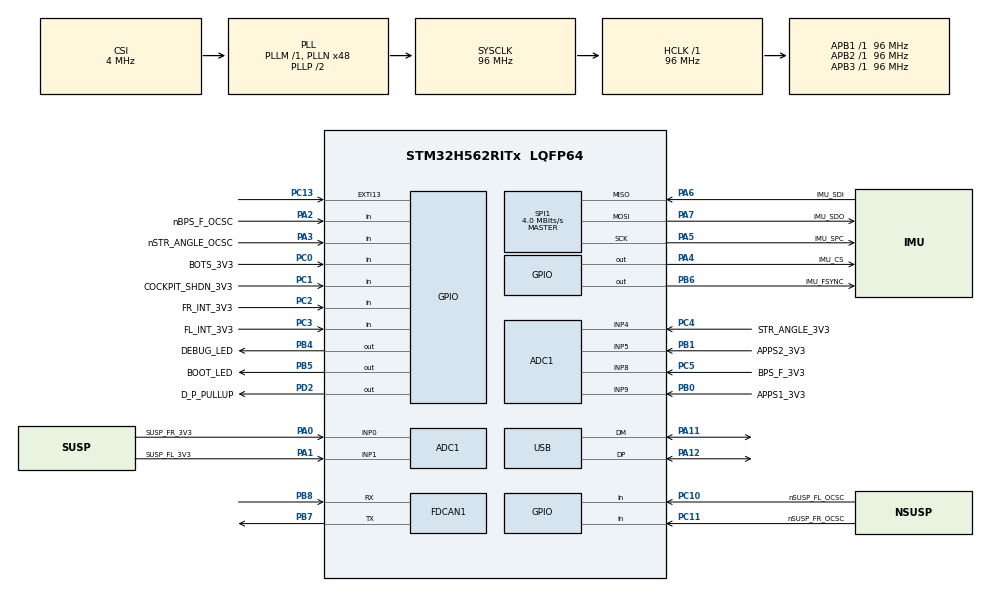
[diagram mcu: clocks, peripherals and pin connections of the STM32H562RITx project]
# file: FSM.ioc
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ADC1.Channel-3\#ChannelRegularConversion=ADC_CHANNEL_1
ADC1.Channel-4\#ChannelRegularConversion=ADC_CHANNEL_0
ADC1.Channel-5\#ChannelRegularConversion=ADC_CHANNEL_5
ADC1.Channel-6\#ChannelRegularConversion=ADC_CHANNEL_8
ADC1.Channel-7\#ChannelRegularConversion=ADC_CHANNEL_4
ADC1.Channel-8\#ChannelRegularConversion=ADC_CHANNEL_9
ADC1.ContinuousConvMode=DISABLE
ADC1.ConversionDataManagement=ADC_CONVERSIONDATA_DMA_CIRCULAR
ADC1.DMAContinuousRequests=ENABLE
ADC1.EOCSelection=ADC_EOC_SEQ_CONV
ADC1.ExternalTrigConv=ADC_EXTERNALTRIG_T2_TRGO
ADC1.MonitoredBy-3\#ChannelRegularConversion=__NULL
ADC1.MonitoredBy-4\#ChannelRegularConversion=__NULL
ADC1.MonitoredBy-5\#ChannelRegularConversion=__NULL
ADC1.MonitoredBy-6\#ChannelRegularConversion=__NULL
ADC1.MonitoredBy-7\#ChannelRegularConversion=__NULL
ADC1.MonitoredBy-8\#ChannelRegularConversion=__NULL
ADC1.NbrOfConversion=6
ADC1.NbrOfConversionFlag=1
ADC1.OffsetNumber-3\#ChannelRegularConversion=ADC_OFFSET_NONE
ADC1.OffsetNumber-4\#ChannelRegularConversion=ADC_OFFSET_NONE
ADC1.OffsetNumber-5\#ChannelRegularConversion=ADC_OFFSET_NONE
ADC1.OffsetNumber-6\#ChannelRegularConversion=ADC_OFFSET_NONE
ADC1.OffsetNumber-7\#ChannelRegularConversion=ADC_OFFSET_NONE
ADC1.OffsetNumber-8\#ChannelRegularConversion=ADC_OFFSET_NONE
ADC1.Rank-3\#ChannelRegularConversion=1
ADC1.Rank-4\#ChannelRegularConversion=2
ADC1.Rank-5\#ChannelRegularConversion=3
ADC1.Rank-6\#ChannelRegularConversion=4
ADC1.Rank-7\#ChannelRegularConversion=5
ADC1.Rank-8\#ChannelRegularConversion=6
ADC1.SamplingTime-3\#ChannelRegularConversion=ADC_SAMPLETIME_47CYCLES_5
ADC1.SamplingTime-4\#ChannelRegularConversion=ADC_SAMPLETIME_47CYCLES_5
ADC1.SamplingTime-5\#ChannelRegularConversion=ADC_SAMPLETIME_47CYCLES_5
ADC1.SamplingTime-6\#ChannelRegularConversion=ADC_SAMPLETIME_47CYCLES_5
ADC1.SamplingTime-7\#ChannelRegularConversion=ADC_SAMPLETIME_47CYCLES_5
ADC1.SamplingTime-8\#ChannelRegularConversion=ADC_SAMPLETIME_47CYCLES_5
ADC1.master=1
BOOTPATH.BootPathName=LEGACY
BOOTPATH.UserSelectedBootPath=LEGACY
CORTEX_M33_NS.userName=CORTEX_M33
FDCAN1.AutoRetransmission=ENABLE
FDCAN1.CalculateBaudRateNominal=1000000
FDCAN1.CalculateTimeBitNominal=1000
FDCAN1.CalculateTimeQuantumNominal=62.5
FDCAN1.DataPrescaler=3
FDCAN1.DataSyncJumpWidth=2
FDCAN1.DataTimeSeg1=5
FDCAN1.DataTimeSeg2=2
FDCAN1.ExtFiltersNbr=1
FDCAN1.FrameFormat=FDCAN_FRAME_FD_NO_BRS
FDCAN1.NominalPrescaler=6
FDCAN1.NominalSyncJumpWidth=2
FDCAN1.NominalTimeSeg1=13
FDCAN1.NominalTimeSeg2=2
FDCAN1.StdFiltersNbr=1
GPDMA1.CIRCULARMODE_GPDMACH0=ENABLE
GPDMA1.DESTDATAWIDTH_GPDMACH0=DMA_DEST_DATAWIDTH_HALFWORD
GPDMA1.DESTINC_GPDMACH0=DMA_DINC_INCREMENTED
GPDMA1.IPHANDLE_GPDMACH0-SIMPLEREQUEST_GPDMACH0=__NULL
GPDMA1.REQUEST_GPDMACH0=GPDMA1_REQUEST_ADC1
GPDMA1.SRCDATAWIDTH_GPDMACH0=DMA_SRC_DATAWIDTH_HALFWORD
GPDMA1.TRANSFERALLOCATEDPORTDEST_GPDMACH0=DMA_DEST_ALLOCATED_PORT0
IWDG.Reload=LSI_FREQUENCY/IWDG_PRESCALER/IWDG_RESET_FREQUENCY
Mcu.Family=STM32H5
Mcu.Name=STM32H562RITx
Mcu.Package=LQFP64
Mcu.UserConstants=TIM2_ARR,(TIMx_FREQUENCY / TIM2_PRESCALER / TIM2_FREQUENCY);TIM2_PRESCALER,250;TIM2_FREQUENCY,1000;TIMx_FREQUENCY,96000000;IWDG_RESET_FREQUENCY,5;IWDG_PRESCALER,4;LSI_FREQUENCY,32000
NVIC.ADC1_IRQn=true\:5\:0\:true\:false\:true\:true\:true\:true
NVIC.EXTI13_IRQn=true\:5\:0\:true\:false\:true\:true\:true\:true
NVIC.FDCAN1_IT0_IRQn=true\:5\:0\:true\:false\:true\:true\:true\:true
NVIC.FDCAN1_IT1_IRQn=true\:5\:0\:true\:false\:true\:true\:true\:true
NVIC.GPDMA1_Channel0_IRQn=true\:5\:0\:true\:false\:true\:false\:true\:true
NVIC.PriorityGroup=NVIC_PRIORITYGROUP_4
NVIC.SPI1_IRQn=true\:5\:0\:true\:false\:true\:true\:true\:true
NVIC.TIM2_IRQn=true\:5\:0\:true\:false\:true\:true\:true\:true
NVIC.TIM6_IRQn=true\:15\:0\:false\:false\:true\:false\:true\:true
NVIC.TIM7_IRQn=true\:5\:0\:true\:false\:true\:true\:true\:true
NVIC.TimeBase=TIM6_IRQn
NVIC.TimeBaseIP=TIM6
NVIC.USB_DRD_FS_IRQn=true\:5\:0\:true\:false\:true\:true\:true\:true
PA0.GPIO_Label=SUSP_FR_3V3
PA0.Signal=ADCx_INP0
PA1.GPIO_Label=SUSP_FL_3V3
PA1.Signal=ADCx_INP1
PA11.Mode=Device
PA11.Signal=USB_DM
PA12.Mode=Device
PA12.Signal=USB_DP
PA13(JTMS/SWDIO).Mode=Trace_Asynchronous_SW
PA13(JTMS/SWDIO).Signal=DEBUG_JTMS-SWDIO
PA14(JTCK/SWCLK).Mode=Trace_Asynchronous_SW
PA14(JTCK/SWCLK).Signal=DEBUG_JTCK-SWCLK
PA2.GPIO_Label=nBPS_F_OCSC
PA2.Signal=GPIO_Input
PA3.GPIO_Label=nSTR_ANGLE_OCSC
PA3.Signal=GPIO_Input
PA4.GPIO_Label=IMU_CS
PA4.PinState=GPIO_PIN_SET
PA4.Signal=GPIO_Output
PA5.GPIO_Label=IMU_SPC
PA5.Mode=Full_Duplex_Master
PA5.Signal=SPI1_SCK
PA6.GPIO_Label=IMU_SDI
PA6.Mode=Full_Duplex_Master
PA6.Signal=SPI1_MISO
PA7.GPIO_Label=IMU_SDO
PA7.Mode=Full_Duplex_Master
PA7.Signal=SPI1_MOSI
PB0.GPIO_Label=APPS1_3V3
PB0.Signal=ADCx_INP9
PB1.GPIO_Label=APPS2_3V3
PB1.Signal=ADCx_INP5
PB3(JTDO/TRACESWO).Mode=Trace_Asynchronous_SW
PB3(JTDO/TRACESWO).Signal=DEBUG_JTDO-SWO
PB4(NJTRST).GPIO_Label=DEBUG_LED
PB4(NJTRST).Signal=GPIO_Output
PB5.GPIO_Label=BOOT_LED
PB5.Signal=GPIO_Output
PB6.GPIO_Label=IMU_FSYNC
PB6.Signal=GPIO_Output
PB7.Mode=FDCAN_Activate
PB7.Signal=FDCAN1_TX
PB8.Mode=FDCAN_Activate
PB8.Signal=FDCAN1_RX
PC0.GPIO_Label=BOTS_3V3
PC0.Signal=GPIO_Input
PC1.GPIO_Label=COCKPIT_SHDN_3V3
PC1.Signal=GPIO_Input
PC10.GPIO_Label=nSUSP_FL_OCSC
PC10.Signal=GPIO_Input
PC11.GPIO_Label=nSUSP_FR_OCSC
PC11.Signal=GPIO_Input
PC13.Signal=GPXTI13
PC2.GPIO_Label=FR_INT_3V3
PC2.Signal=GPIO_Input
PC3.GPIO_Label=FL_INT_3V3
PC3.Signal=GPIO_Input
PC4.GPIO_Label=STR_ANGLE_3V3
PC4.Signal=ADCx_INP4
PC5.GPIO_Label=BPS_F_3V3
PC5.Signal=ADCx_INP8
PD2.GPIO_Label=D_P_PULLUP
PD2.GPIO_ModeDefaultOutputPP=GPIO_MODE_OUTPUT_PP
PD2.GPIO_PuPd=GPIO_NOPULL
PD2.Signal=GPIO_Output
PH0-OSC_IN(PH0).Mode=HSE-External-Oscillator
PH0-OSC_IN(PH0).Signal=RCC_OSC_IN
PH1-OSC_OUT(PH1).Mode=HSE-External-Oscillator
PH1-OSC_OUT(PH1).Signal=RCC_OSC_OUT
ProjectManager.HeapSize=0x200
ProjectManager.StackSize=0x400
ProjectManager.TargetToolchain=STM32CubeIDE
RCC.ADCFreq_Value=96000000
RCC.AHBFreq_Value=96000000
RCC.APB1Freq_Value=96000000
RCC.APB1TimFreq_Value=96000000
RCC.APB2Freq_Value=96000000
RCC.APB2TimFreq_Value=96000000
RCC.APB3Freq_Value=96000000
RCC.CKPERSourceSelection=RCC_CLKPSOURCE_HSE
RCC.CSI_VALUE=4000000
RCC.CortexFreq_Value=96000000
RCC.EPOD_VALUE=4000000
RCC.FDCANClockSelection=RCC_FDCANCLKSOURCE_PLL1Q
RCC.HCLKFreq_Value=96000000
RCC.HSE_VALUE=8000000
RCC.HSI48_VALUE=48000000
RCC.HSI_VALUE=64000000
RCC.LSE_VALUE=32768
RCC.LSIRC_VALUE=32000
RCC.PLL2FRACN=0
RCC.PLL2Source=RCC_PLL2_SOURCE_HSE
RCC.PLL3FRACN=0
RCC.PLL3Source=RCC_PLL3_SOURCE_HSE
RCC.PLLFRACN=0
RCC.PLLN=48
RCC.SPI1CLockSelection=RCC_SPI1CLKSOURCE_CLKP
RCC.SYSCLKFreq_VALUE=96000000
RCC.SYSCLKSource=RCC_SYSCLKSOURCE_PLLCLK
RCC.USBFreq_Value=48000000
RCC.VCOOutputFreq_Value=192000000
SH.ADCx_INP0.0=ADC1_INP0,IN0-Single-Ended
SH.ADCx_INP1.0=ADC1_INP1,IN1-Single-Ended
SH.ADCx_INP4.0=ADC1_INP4,IN4-Single-Ended
SH.ADCx_INP5.0=ADC1_INP5,IN5-Single-Ended
SH.ADCx_INP8.0=ADC1_INP8,IN8-Single-Ended
SH.ADCx_INP9.0=ADC1_INP9,IN9-Single-Ended
SPI1.BaudRatePrescaler=SPI_BAUDRATEPRESCALER_2
SPI1.CalculateBaudRate=4.0 MBits/s
SPI1.DataSize=SPI_DATASIZE_8BIT
SPI1.Direction=SPI_DIRECTION_2LINES
SPI1.Mode=SPI_MODE_MASTER
SPI1.VirtualType=VM_MASTER
TIM2.AutoReloadPreload=TIM_AUTORELOAD_PRELOAD_ENABLE
TIM2.PeriodNoDither=TIM2_ARR -1
TIM2.Prescaler=TIM2_PRESCALER - 1
TIM2.TIM_MasterOutputTrigger=TIM_TRGO_UPDATE
TIM7.PeriodNoDither=960-1
TIM7.Prescaler=10-1
USB.VirtualMode=Device_Only
VP_BOOTPATH_VS_BOOTPATH.Mode=BP_Activate
VP_CORTEX_M33_NS_VS_Hclk.Mode=Hclk_Mode
VP_GPDMA1_VS_GPDMACH0.Mode=SIMPLEREQUEST_GPDMACH0
VP_IWDG_VS_IWDG.Mode=IWDG_Activate
VP_MEMORYMAP_VS_MEMORYMAP.Mode=CurAppReg
VP_PWR_VS_LPOM.Mode=PowerOptimisation
VP_PWR_VS_SECSignals.Mode=Security/Privilege
VP_SYS_VS_tim6.Mode=TIM6
VP_TIM2_VS_ClockSourceINT.Mode=Internal
VP_TIM7_VS_ClockSourceINT.Mode=Enable_Timer
board=custom

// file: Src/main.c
/* USER CODE BEGIN Header */
/**
 ******************************************************************************
 * @file           : main.c
 * @brief          : Main program body
 ******************************************************************************
 * @attention
 *
 * Copyright (c) 2025 STMicroelectronics.
 * All rights reserved.
 *
 * This software is licensed under terms that can be found in the LICENSE file
 * in the root directory of this software component.
 * If no LICENSE file comes with this software, it is provided AS-IS.
 *
 ******************************************************************************
 */
/* USER CODE END Header */
#include "main.h"

/* USER CODE BEGIN Includes */
#include "tasks.h"
#include "hw_error.hpp"
/* USER CODE END Includes */

ADC_HandleTypeDef hadc1;
DMA_NodeTypeDef   Node_GPDMA1_Channel0;
DMA_QListTypeDef  List_GPDMA1_Channel0;
DMA_HandleTypeDef handle_GPDMA1_Channel0;

FDCAN_HandleTypeDef hfdcan1;

IWDG_HandleTypeDef hiwdg;

SPI_HandleTypeDef hspi1;

TIM_HandleTypeDef htim2;
TIM_HandleTypeDef htim7;

PCD_HandleTypeDef hpcd_USB_DRD_FS;

void        SystemClock_Config(void);
void        PeriphCommonClock_Config(void);
static void MX_GPIO_Init(void);
static void MX_GPDMA1_Init(void);
static void MX_ADC1_Init(void);
static void MX_FDCAN1_Init(void);
static void MX_USB_PCD_Init(void);
static void MX_SPI1_Init(void);
static void MX_TIM2_Init(void);
static void MX_IWDG_Init(void);
static void MX_TIM7_Init(void);

int main(void)
{
    /* USER CODE BEGIN 1 */
    tasks_preInit();
    /* USER CODE END 1 */

    /* MCU Configuration--------------------------------------------------------*/

    /* Reset of all peripherals, Initializes the Flash interface and the Systick. */
    HAL_Init();

    /* Configure the system clock */
    SystemClock_Config();

    /* Configure the peripherals common clocks */
    PeriphCommonClock_Config();

    /* Initialize all configured peripherals */
    MX_GPIO_Init();
    MX_GPDMA1_Init();
    MX_ADC1_Init();
    MX_FDCAN1_Init();
    MX_USB_PCD_Init();
    MX_SPI1_Init();
    MX_TIM2_Init();
    MX_IWDG_Init();
    MX_TIM7_Init();
    /* USER CODE BEGIN 2 */
    tasks_init();
    /* USER CODE END 2 */

    /* Infinite loop */
    while (1)
    {

    }
}

void SystemClock_Config(void)
{
    RCC_OscInitTypeDef RCC_OscInitStruct = { 0 };
    RCC_ClkInitTypeDef RCC_ClkInitStruct = { 0 };

    /** Configure the main internal regulator output voltage
     */
    __HAL_PWR_VOLTAGESCALING_CONFIG(PWR_REGULATOR_VOLTAGE_SCALE3);

    while (!__HAL_PWR_GET_FLAG(PWR_FLAG_VOSRDY))
    {
    }

    /** Initializes the RCC Oscillators according to the specified parameters
     * in the RCC_OscInitTypeDef structure.
     */
    RCC_OscInitStruct.OscillatorType =
        RCC_OSCILLATORTYPE_HSI48 | RCC_OSCILLATORTYPE_LSI | RCC_OSCILLATORTYPE_HSE | RCC_OSCILLATORTYPE_CSI;
    RCC_OscInitStruct.HSEState            = RCC_HSE_ON;
    RCC_OscInitStruct.LSIState            = RCC_LSI_ON;
    RCC_OscInitStruct.HSI48State          = RCC_HSI48_ON;
    RCC_OscInitStruct.CSIState            = RCC_CSI_ON;
    RCC_OscInitStruct.CSICalibrationValue = RCC_CSICALIBRATION_DEFAULT;
    RCC_OscInitStruct.PLL.PLLState        = RCC_PLL_ON;
    RCC_OscInitStruct.PLL.PLLSource       = RCC_PLL1_SOURCE_CSI;
    RCC_OscInitStruct.PLL.PLLM            = 1;
    RCC_OscInitStruct.PLL.PLLN            = 48;
    RCC_OscInitStruct.PLL.PLLP            = 2;
    RCC_OscInitStruct.PLL.PLLQ            = 2;
    RCC_OscInitStruct.PLL.PLLR            = 2;
    RCC_OscInitStruct.PLL.PLLRGE          = RCC_PLL1_VCIRANGE_2;
    RCC_OscInitStruct.PLL.PLLVCOSEL       = RCC_PLL1_VCORANGE_WIDE;
    RCC_OscInitStruct.PLL.PLLFRACN        = 0;
    if (HAL_RCC_OscConfig(&RCC_OscInitStruct) != HAL_OK)
    {
        Error_Handler();
    }

    /** Initializes the CPU, AHB and APB buses clocks
     */
    RCC_ClkInitStruct.ClockType =
        RCC_CLOCKTYPE_HCLK | RCC_CLOCKTYPE_SYSCLK | RCC_CLOCKTYPE_PCLK1 | RCC_CLOCKTYPE_PCLK2 | RCC_CLOCKTYPE_PCLK3;
    RCC_ClkInitStruct.SYSCLKSource   = RCC_SYSCLKSOURCE_PLLCLK;
    RCC_ClkInitStruct.AHBCLKDivider  = RCC_SYSCLK_DIV1;
    RCC_ClkInitStruct.APB1CLKDivider = RCC_HCLK_DIV1;
    RCC_ClkInitStruct.APB2CLKDivider = RCC_HCLK_DIV1;
    RCC_ClkInitStruct.APB3CLKDivider = RCC_HCLK_DIV1;

    if (HAL_RCC_ClockConfig(&RCC_ClkInitStruct, FLASH_LATENCY_4) != HAL_OK)
    {
        Error_Handler();
    }

    /** Configure the programming delay
     */
    __HAL_FLASH_SET_PROGRAM_DELAY(FLASH_PROGRAMMING_DELAY_2);
}

void PeriphCommonClock_Config(void)
{
    RCC_PeriphCLKInitTypeDef PeriphClkInitStruct = { 0 };

    /** Initializes the peripherals clock
     */
    PeriphClkInitStruct.PeriphClockSelection = RCC_PERIPHCLK_CKPER;
    PeriphClkInitStruct.CkperClockSelection  = RCC_CLKPSOURCE_HSE;
    if (HAL_RCCEx_PeriphCLKConfig(&PeriphClkInitStruct) != HAL_OK)
    {
        Error_Handler();
    }
}

static void MX_ADC1_Init(void)
{

    ADC_ChannelConfTypeDef sConfig = { 0 };

    /** Common config
     */
    hadc1.Instance                   = ADC1;
    hadc1.Init.ClockPrescaler        = ADC_CLOCK_ASYNC_DIV2;
    hadc1.Init.Resolution            = ADC_RESOLUTION_12B;
    hadc1.Init.DataAlign             = ADC_DATAALIGN_RIGHT;
    hadc1.Init.ScanConvMode          = ADC_SCAN_ENABLE;
    hadc1.Init.EOCSelection          = ADC_EOC_SEQ_CONV;
    hadc1.Init.LowPowerAutoWait      = DISABLE;
    hadc1.Init.ContinuousConvMode    = DISABLE;
    hadc1.Init.NbrOfConversion       = 6;
    hadc1.Init.DiscontinuousConvMode = DISABLE;
    hadc1.Init.ExternalTrigConv      = ADC_EXTERNALTRIG_T2_TRGO;
    hadc1.Init.ExternalTrigConvEdge  = ADC_EXTERNALTRIGCONVEDGE_RISING;
    hadc1.Init.DMAContinuousRequests = ENABLE;
    hadc1.Init.SamplingMode          = ADC_SAMPLING_MODE_NORMAL;
    hadc1.Init.Overrun               = ADC_OVR_DATA_PRESERVED;
    hadc1.Init.OversamplingMode      = DISABLE;
    if (HAL_ADC_Init(&hadc1) != HAL_OK)
    {
        Error_Handler();
    }

    /** Configure Regular Channel
     */
    sConfig.Channel      = ADC_CHANNEL_1;
    sConfig.Rank         = ADC_REGULAR_RANK_1;
    sConfig.SamplingTime = ADC_SAMPLETIME_47CYCLES_5;
    sConfig.SingleDiff   = ADC_SINGLE_ENDED;
    sConfig.OffsetNumber = ADC_OFFSET_NONE;
    sConfig.Offset       = 0;
    if (HAL_ADC_ConfigChannel(&hadc1, &sConfig) != HAL_OK)
    {
        Error_Handler();
    }

    /** Configure Regular Channel
     */
    sConfig.Channel = ADC_CHANNEL_0;
    sConfig.Rank    = ADC_REGULAR_RANK_2;
    if (HAL_ADC_ConfigChannel(&hadc1, &sConfig) != HAL_OK)
    {
        Error_Handler();
    }

    /** Configure Regular Channel
     */
    sConfig.Channel = ADC_CHANNEL_5;
    sConfig.Rank    = ADC_REGULAR_RANK_3;
    if (HAL_ADC_ConfigChannel(&hadc1, &sConfig) != HAL_OK)
    {
        Error_Handler();
    }

    /** Configure Regular Channel
     */
    sConfig.Channel = ADC_CHANNEL_8;
    sConfig.Rank    = ADC_REGULAR_RANK_4;
    if (HAL_ADC_ConfigChannel(&hadc1, &sConfig) != HAL_OK)
    {
        Error_Handler();
    }

    /** Configure Regular Channel
     */
    sConfig.Channel = ADC_CHANNEL_4;
    sConfig.Rank    = ADC_REGULAR_RANK_5;
    if (HAL_ADC_ConfigChannel(&hadc1, &sConfig) != HAL_OK)
    {
        Error_Handler();
    }

    /** Configure Regular Channel
     */
    sConfig.Channel = ADC_CHANNEL_9;
    sConfig.Rank    = ADC_REGULAR_RANK_6;
    if (HAL_ADC_ConfigChannel(&hadc1, &sConfig) != HAL_OK)
    {
        Error_Handler();
    }
}

static void MX_FDCAN1_Init(void)
{

    hfdcan1.Instance                  = FDCAN1;
    hfdcan1.Init.ClockDivider         = FDCAN_CLOCK_DIV1;
    hfdcan1.Init.FrameFormat          = FDCAN_FRAME_FD_NO_BRS;
    hfdcan1.Init.Mode                 = FDCAN_MODE_NORMAL;
    hfdcan1.Init.AutoRetransmission   = ENABLE;
    hfdcan1.Init.TransmitPause        = DISABLE;
    hfdcan1.Init.ProtocolException    = DISABLE;
    hfdcan1.Init.NominalPrescaler     = 6;
    hfdcan1.Init.NominalSyncJumpWidth = 2;
    hfdcan1.Init.NominalTimeSeg1      = 13;
    hfdcan1.Init.NominalTimeSeg2      = 2;
    hfdcan1.Init.DataPrescaler        = 3;
    hfdcan1.Init.DataSyncJumpWidth    = 2;
    hfdcan1.Init.DataTimeSeg1         = 5;
    hfdcan1.Init.DataTimeSeg2         = 2;
    hfdcan1.Init.StdFiltersNbr        = 1;
    hfdcan1.Init.ExtFiltersNbr        = 1;
    hfdcan1.Init.TxFifoQueueMode      = FDCAN_TX_FIFO_OPERATION;
    if (HAL_FDCAN_Init(&hfdcan1) != HAL_OK)
    {
        Error_Handler();
    }
}

static void MX_GPDMA1_Init(void)
{

    /* Peripheral clock enable */
    __HAL_RCC_GPDMA1_CLK_ENABLE();

    /* GPDMA1 interrupt Init */
    HAL_NVIC_SetPriority(GPDMA1_Channel0_IRQn, 5, 0);
    HAL_NVIC_EnableIRQ(GPDMA1_Channel0_IRQn);

}

static void MX_IWDG_Init(void)
{

    /* USER CODE BEGIN IWDG_Init 1 */
#ifndef WATCHDOG_DISABLED
    /* USER CODE END IWDG_Init 1 */
    hiwdg.Instance       = IWDG;
    hiwdg.Init.Prescaler = IWDG_PRESCALER_4;
    hiwdg.Init.Window    = 4095;
    hiwdg.Init.Reload    = LSI_FREQUENCY / IWDG_PRESCALER / IWDG_RESET_FREQUENCY;
    hiwdg.Init.EWI       = 0;
    if (HAL_IWDG_Init(&hiwdg) != HAL_OK)
    {
        Error_Handler();
    }
    /* USER CODE BEGIN IWDG_Init 2 */
#endif
    /* USER CODE END IWDG_Init 2 */
}

static void MX_SPI1_Init(void)
{

    /* SPI1 parameter configuration*/
    hspi1.Instance                     = SPI1;
    hspi1.Init.Mode                    = SPI_MODE_MASTER;
    hspi1.Init.Direction               = SPI_DIRECTION_2LINES;
    hspi1.Init.DataSize                = SPI_DATASIZE_8BIT;
    hspi1.Init.CLKPolarity             = SPI_POLARITY_LOW;
    hspi1.Init.CLKPhase                = SPI_PHASE_1EDGE;
    hspi1.Init.NSS                     = SPI_NSS_SOFT;
    hspi1.Init.BaudRatePrescaler       = SPI_BAUDRATEPRESCALER_2;
    hspi1.Init.FirstBit                = SPI_FIRSTBIT_MSB;
    hspi1.Init.TIMode                  = SPI_TIMODE_DISABLE;
    hspi1.Init.CRCCalculation          = SPI_CRCCALCULATION_DISABLE;
    hspi1.Init.CRCPolynomial           = 0x7;
    hspi1.Init.NSSPMode                = SPI_NSS_PULSE_ENABLE;
    hspi1.Init.NSSPolarity             = SPI_NSS_POLARITY_LOW;
    hspi1.Init.FifoThreshold           = SPI_FIFO_THRESHOLD_01DATA;
    hspi1.Init.MasterSSIdleness        = SPI_MASTER_SS_IDLENESS_00CYCLE;
    hspi1.Init.MasterInterDataIdleness = SPI_MASTER_INTERDATA_IDLENESS_00CYCLE;
    hspi1.Init.MasterReceiverAutoSusp  = SPI_MASTER_RX_AUTOSUSP_DISABLE;
    hspi1.Init.MasterKeepIOState       = SPI_MASTER_KEEP_IO_STATE_DISABLE;
    hspi1.Init.IOSwap                  = SPI_IO_SWAP_DISABLE;
    hspi1.Init.ReadyMasterManagement   = SPI_RDY_MASTER_MANAGEMENT_INTERNALLY;
    hspi1.Init.ReadyPolarity           = SPI_RDY_POLARITY_HIGH;
    if (HAL_SPI_Init(&hspi1) != HAL_OK)
    {
        Error_Handler();
    }
}

static void MX_TIM2_Init(void)
{

    TIM_ClockConfigTypeDef  sClockSourceConfig = { 0 };
    TIM_MasterConfigTypeDef sMasterConfig      = { 0 };

    htim2.Instance               = TIM2;
    htim2.Init.Prescaler         = TIM2_PRESCALER - 1;
    htim2.Init.CounterMode       = TIM_COUNTERMODE_UP;
    htim2.Init.Period            = 383;
    htim2.Init.ClockDivision     = TIM_CLOCKDIVISION_DIV1;
    htim2.Init.AutoReloadPreload = TIM_AUTORELOAD_PRELOAD_ENABLE;
    if (HAL_TIM_Base_Init(&htim2) != HAL_OK)
    {
        Error_Handler();
    }
    sClockSourceConfig.ClockSource = TIM_CLOCKSOURCE_INTERNAL;
    if (HAL_TIM_ConfigClockSource(&htim2, &sClockSourceConfig) != HAL_OK)
    {
        Error_Handler();
    }
    sMasterConfig.MasterOutputTrigger = TIM_TRGO_UPDATE;
    sMasterConfig.MasterSlaveMode     = TIM_MASTERSLAVEMODE_DISABLE;
    if (HAL_TIMEx_MasterConfigSynchronization(&htim2, &sMasterConfig) != HAL_OK)
    {
        Error_Handler();
    }
}

static void MX_TIM7_Init(void)
{

    TIM_MasterConfigTypeDef sMasterConfig = { 0 };

    htim7.Instance               = TIM7;
    htim7.Init.Prescaler         = 10 - 1;
    htim7.Init.CounterMode       = TIM_COUNTERMODE_UP;
    htim7.Init.Period            = 959;
    htim7.Init.AutoReloadPreload = TIM_AUTORELOAD_PRELOAD_DISABLE;
    if (HAL_TIM_Base_Init(&htim7) != HAL_OK)
    {
        Error_Handler();
    }
    sMasterConfig.MasterOutputTrigger = TIM_TRGO_RESET;
    sMasterConfig.MasterSlaveMode     = TIM_MASTERSLAVEMODE_DISABLE;
    if (HAL_TIMEx_MasterConfigSynchronization(&htim7, &sMasterConfig) != HAL_OK)
    {
        Error_Handler();
    }
}

static void MX_USB_PCD_Init(void)
{

    hpcd_USB_DRD_FS.Instance                      = USB_DRD_FS;
    hpcd_USB_DRD_FS.Init.dev_endpoints            = 8;
    hpcd_USB_DRD_FS.Init.speed                    = USBD_FS_SPEED;
    hpcd_USB_DRD_FS.Init.phy_itface               = PCD_PHY_EMBEDDED;
    hpcd_USB_DRD_FS.Init.Sof_enable               = DISABLE;
    hpcd_USB_DRD_FS.Init.low_power_enable         = DISABLE;
    hpcd_USB_DRD_FS.Init.lpm_enable               = DISABLE;
    hpcd_USB_DRD_FS.Init.battery_charging_enable  = DISABLE;
    hpcd_USB_DRD_FS.Init.vbus_sensing_enable      = DISABLE;
    hpcd_USB_DRD_FS.Init.bulk_doublebuffer_enable = DISABLE;
    hpcd_USB_DRD_FS.Init.iso_singlebuffer_enable  = DISABLE;
    if (HAL_PCD_Init(&hpcd_USB_DRD_FS) != HAL_OK)
    {
        Error_Handler();
    }
}

static void MX_GPIO_Init(void)
{
    GPIO_InitTypeDef GPIO_InitStruct = { 0 };

    /* GPIO Ports Clock Enable */
    __HAL_RCC_GPIOC_CLK_ENABLE();
    __HAL_RCC_GPIOH_CLK_ENABLE();
    __HAL_RCC_GPIOA_CLK_ENABLE();
    __HAL_RCC_GPIOB_CLK_ENABLE();
    __HAL_RCC_GPIOD_CLK_ENABLE();

    /*Configure GPIO pin Output Level */
    HAL_GPIO_WritePin(IMU_CS_GPIO_Port, IMU_CS_Pin, GPIO_PIN_SET);

    /*Configure GPIO pin Output Level */
    HAL_GPIO_WritePin(D_P_PULLUP_GPIO_Port, D_P_PULLUP_Pin, GPIO_PIN_RESET);

    /*Configure GPIO pin Output Level */
    HAL_GPIO_WritePin(GPIOB, DEBUG_LED_Pin | BOOT_LED_Pin | IMU_FSYNC_Pin, GPIO_PIN_RESET);

    /*Configure GPIO pin : PC13 */
    GPIO_InitStruct.Pin  = GPIO_PIN_13;
    GPIO_InitStruct.Mode = GPIO_MODE_IT_RISING;
    GPIO_InitStruct.Pull = GPIO_NOPULL;
    HAL_GPIO_Init(GPIOC, &GPIO_InitStruct);

    /*Configure GPIO pins : BOTS_3V3_Pin COCKPIT_SHDN_3V3_Pin FR_INT_3V3_Pin FL_INT_3V3_Pin
                             nSUSP_FL_OCSC_Pin nSUSP_FR_OCSC_Pin */
    GPIO_InitStruct.Pin =
        BOTS_3V3_Pin | COCKPIT_SHDN_3V3_Pin | FR_INT_3V3_Pin | FL_INT_3V3_Pin | nSUSP_FL_OCSC_Pin | nSUSP_FR_OCSC_Pin;
    GPIO_InitStruct.Mode = GPIO_MODE_INPUT;
    GPIO_InitStruct.Pull = GPIO_NOPULL;
    HAL_GPIO_Init(GPIOC, &GPIO_InitStruct);

    /*Configure GPIO pins : nBPS_F_OCSC_Pin nSTR_ANGLE_OCSC_Pin */
    GPIO_InitStruct.Pin  = nBPS_F_OCSC_Pin | nSTR_ANGLE_OCSC_Pin;
    GPIO_InitStruct.Mode = GPIO_MODE_INPUT;
    GPIO_InitStruct.Pull = GPIO_NOPULL;
    HAL_GPIO_Init(GPIOA, &GPIO_InitStruct);

    /*Configure GPIO pin : IMU_CS_Pin */
    GPIO_InitStruct.Pin   = IMU_CS_Pin;
    GPIO_InitStruct.Mode  = GPIO_MODE_OUTPUT_PP;
    GPIO_InitStruct.Pull  = GPIO_NOPULL;
    GPIO_InitStruct.Speed = GPIO_SPEED_FREQ_LOW;
    HAL_GPIO_Init(IMU_CS_GPIO_Port, &GPIO_InitStruct);

    /*Configure GPIO pin : D_P_PULLUP_Pin */
    GPIO_InitStruct.Pin   = D_P_PULLUP_Pin;
    GPIO_InitStruct.Mode  = GPIO_MODE_OUTPUT_PP;
    GPIO_InitStruct.Pull  = GPIO_NOPULL;
    GPIO_InitStruct.Speed = GPIO_SPEED_FREQ_LOW;
    HAL_GPIO_Init(D_P_PULLUP_GPIO_Port, &GPIO_InitStruct);

    /*Configure GPIO pins : DEBUG_LED_Pin BOOT_LED_Pin IMU_FSYNC_Pin */
    GPIO_InitStruct.Pin   = DEBUG_LED_Pin | BOOT_LED_Pin | IMU_FSYNC_Pin;
    GPIO_InitStruct.Mode  = GPIO_MODE_OUTPUT_PP;
    GPIO_InitStruct.Pull  = GPIO_NOPULL;
    GPIO_InitStruct.Speed = GPIO_SPEED_FREQ_LOW;
    HAL_GPIO_Init(GPIOB, &GPIO_InitStruct);

    /* EXTI interrupt init*/
    HAL_NVIC_SetPriority(EXTI13_IRQn, 5, 0);
    HAL_NVIC_EnableIRQ(EXTI13_IRQn);

}

void HAL_TIM_PeriodElapsedCallback(TIM_HandleTypeDef *htim)
{
    if (htim->Instance == TIM6)
    {
        HAL_IncTick();
    }
}

void Error_Handler(void)
{
    __disable_irq();
    while (1)
    {
    }
}
